VERSION ""

NS_ :

BS_:

BU_: VCM INVmc HVAC TCU OBCpd HVBAT

BO_ 3221225472 VECTOR__INDEPENDENT_SIG_MSG: 0 Vector__XXX
 SG_ Unknown_55B_5 m3 : 40|8@1+ (1,0) [0|0] "" Vector__XXX
 SG_ StopChargeMaybe : 52|4@1+ (1,0) [0|0] "" Vector__XXX
 SG_ Unknown_59E_3 : 32|8@1+ (1,0) [0|0] "" Vector__XXX
 SG_ Unknown_1D4_5 : 40|8@1+ (1,0) [0|0] "" Vector__XXX
 SG_ Unknown_1D4_6 : 48|8@1+ (1,0) [0|0] "" Vector__XXX
 SG_ HCM_WakeUpSleepCommand : 24|8@1+ (1,0) [0|0] "" Vector__XXX
 SG_ Unknown_50B_4 : 32|8@1+ (1,0) [0|0] "" Vector__XXX
 SG_ Unknown_50B_5 : 40|8@1+ (1,0) [0|0] "" Vector__XXX
 SG_ Unknown_50B_6 : 48|8@1+ (1,0) [0|0] "" Vector__XXX
 SG_ Unknown_50C_5_1 m1 : 40|8@1+ (1,0) [0|0] "" Vector__XXX
 SG_ Unknown_50C_5_0 m0 : 40|8@1+ (1,0) [0|0] "" Vector__XXX
 SG_ Unknown_50C_5_2 m2 : 40|8@1+ (1,0) [0|0] "" Vector__XXX
 SG_ Unknown_50C_5_3 m3 : 40|8@1+ (1,0) [0|0] "" Vector__XXX
 SG_ ALU_Question : 32|8@1+ (1,0) [0|0] "" Vector__XXX
 SG_ Mux_50C M : 24|1@1+ (1,0) [0|0] "" Vector__XXX
 SG_ TCSOC : 6|1@1+ (1,0) [0|0] "" Vector__XXX
 SG_ LB_HistData_HighLow_Voltage_Time : 0|4@1+ (1,0) [0|10] "times" Vector__XXX
 SG_ LB_HistData_Tempera_Wakeup_Phase : 9|7@1+ (1,-40) [-40|86] "degC" Vector__XXX
 SG_ LB_Historical_Data_Temperature : 17|7@1+ (1,-40) [-40|86] "degC" Vector__XXX
 SG_ LB_HistData_Integrated_Current : 24|8@1- (0.6,0) [-76.2|76.2] "Ah" Vector__XXX
 SG_ LB_HistData_Degrade_IntRes_Coeff : 33|7@1+ (1,0) [0|100] "%" Vector__XXX
 SG_ LB_Historical_Data_Cell_Voltage : 42|6@1+ (1,0) [0|4380] "mV" Vector__XXX
 SG_ DiagSomething2 : 16|8@1+ (1,0) [0|0] "" Vector__XXX
 SG_ OBC_NormalChargePortConnection : 43|2@0+ (1,0) [0|0] "" Vector__XXX
 SG_ Mux_5BC M : 32|4@1+ (1,0) [0|0] "" Vector__XXX
 SG_ ChargeBars m8 : 20|4@1+ (1,0) [0|15] "-" Vector__XXX
 SG_ CapacityBars m9 : 20|4@1+ (1,0) [0|15] "-" Vector__XXX

BO_ 1468 x5BC: 8 HVBAT
 SG_ LB_Remain_Capacity_GIDS : 7|10@0+ (1,0) [0|500] "gids" Vector__XXX
 SG_ LB_Remaining_Capacity_Segments_0 m0 : 16|8@1+ (1,0) [0|240] "" Vector__XXX
 SG_ LB_Temperature_Segment_For_Dash : 24|8@1+ (0.4166666,0) [0|100] "%" Vector__XXX
 SG_ LB_Capacity_Deterioration_Rate : 33|7@1+ (1,0) [0|100] "%" Vector__XXX
 SG_ LB_Remain_Cap_Segment_Swit_Flag M : 32|1@1+ (1,0) [0|1] "status" Vector__XXX
 SG_ LB_Output_Power_Limit_Reason : 45|3@1+ (1,0) [0|7] "modemask" Vector__XXX
 SG_ LB_Remain_Charge_Time_Condition : 41|5@0+ (1,0) [0|30] "modemask" Vector__XXX
 SG_ LB_Remain_Charge_Time : 52|13@0+ (1,0) [0|8190] "minutes" Vector__XXX
 SG_ LB_MaxGIDS : 44|1@1+ (1,0) [0|1] "" Vector__XXX
 SG_ LB_Remaining_Capacity_Segments_1 m1 : 16|8@1+ (1,0) [0|240] "" Vector__XXX

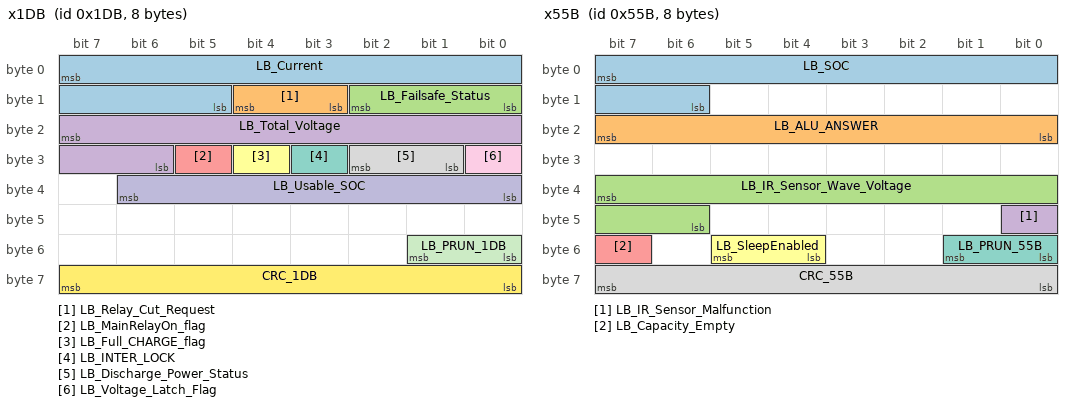
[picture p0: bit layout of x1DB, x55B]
BO_ 475 x1DB: 8 HVBAT
 SG_ LB_Current : 7|11@0- (0.5,0) [-400|200] "A" Vector__XXX
 SG_ LB_Relay_Cut_Request : 11|2@1+ (1,0) [0|0] "MODEMASK" Vector__XXX
 SG_ LB_Failsafe_Status : 8|3@1+ (1,0) [0|0] "MODEMASK" Vector__XXX
 SG_ LB_Total_Voltage : 23|10@0+ (0.5,0) [0|450] "V" Vector__XXX
 SG_ LB_MainRelayOn_flag : 29|1@1+ (1,0) [0|0] "MODEMASK" Vector__XXX
 SG_ LB_Full_CHARGE_flag : 28|1@1+ (1,0) [0|0] "" Vector__XXX
 SG_ LB_INTER_LOCK : 27|1@1+ (1,0) [0|0] "MODEMASK" Vector__XXX
 SG_ LB_Discharge_Power_Status : 25|2@1+ (1,0) [0|0] "MODEMASK" Vector__XXX
 SG_ LB_Voltage_Latch_Flag : 24|1@1+ (1,0) [0|0] "MODEMASK" Vector__XXX
 SG_ LB_Usable_SOC : 32|7@1+ (1,0) [0|0] "" Vector__XXX
 SG_ LB_PRUN_1DB : 48|2@1+ (1,0) [0|0] "" Vector__XXX
 SG_ CRC_1DB : 56|8@1+ (1,0) [0|0] "CRC" Vector__XXX

BO_ 1371 x55B: 8 HVBAT
 SG_ LB_SOC : 7|10@0+ (1,0) [0|1000] "%+1" Vector__XXX
 SG_ LB_ALU_ANSWER : 16|8@1+ (1,0) [85|170] "" Vector__XXX
 SG_ LB_IR_Sensor_Wave_Voltage : 39|10@0+ (1,0) [0|4990] "mV (5000/1024)" Vector__XXX
 SG_ LB_IR_Sensor_Malfunction : 40|1@1+ (1,0) [0|1] "modemask" Vector__XXX
 SG_ LB_Capacity_Empty : 55|1@1+ (1,0) [0|1] "modemask" Vector__XXX
 SG_ LB_SleepEnabled : 53|2@0+ (1,0) [0|3] "modemask" Vector__XXX
 SG_ LB_PRUN_55B : 48|2@1+ (1,0) [0|3] "" Vector__XXX
 SG_ CRC_55B : 56|8@1+ (1,0) [0|0] "CRC" Vector__XXX

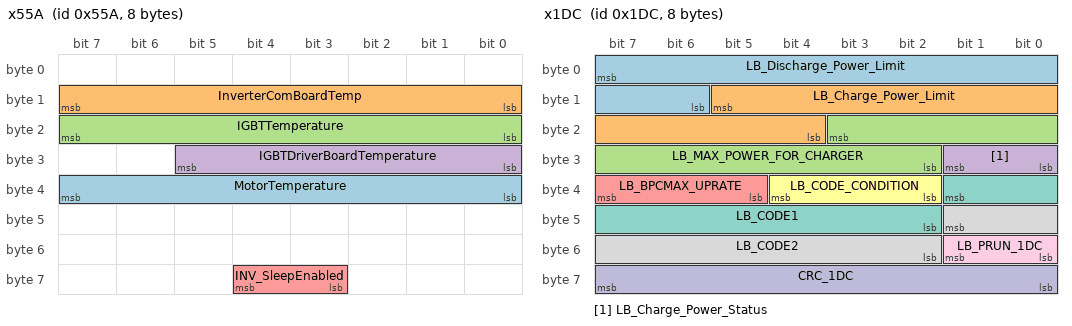
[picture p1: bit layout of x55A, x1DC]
BO_ 1370 x55A: 8 INVmc
 SG_ MotorTemperature : 32|8@1+ (1,0) [0|255] "dC*2" Vector__XXX
 SG_ InverterComBoardTemp : 8|8@1+ (1,0) [0|255] "dC*2" Vector__XXX
 SG_ IGBTTemperature : 16|8@1+ (1,0) [0|255] "dC*2" Vector__XXX
 SG_ IGBTDriverBoardTemperature : 29|6@0+ (1,0) [0|255] "dC*2" Vector__XXX
 SG_ INV_SleepEnabled : 60|2@0+ (1,0) [0|0] "" Vector__XXX

BO_ 476 x1DC: 8 HVBAT
 SG_ LB_Discharge_Power_Limit : 7|10@0+ (0.25,0) [0|254] "kW" Vector__XXX
 SG_ LB_Charge_Power_Limit : 13|10@0+ (0.25,0) [0|254] "kW" Vector__XXX
 SG_ LB_MAX_POWER_FOR_CHARGER : 19|10@0+ (0.1,-10) [-10|90] "kW" Vector__XXX
 SG_ LB_Charge_Power_Status : 24|2@1+ (1,0) [0|0] "MODEMASK" Vector__XXX
 SG_ LB_BPCMAX_UPRATE : 37|3@1+ (1,0) [0|0] "MODEMASK" Vector__XXX
 SG_ LB_CODE_CONDITION : 34|3@1+ (1,0) [0|0] "" Vector__XXX
 SG_ LB_CODE1 : 33|8@0+ (1,0) [0|0] "" Vector__XXX
 SG_ LB_CODE2 : 41|8@0+ (1,0) [0|0] "" Vector__XXX
 SG_ LB_PRUN_1DC : 48|2@1+ (1,0) [0|3] "" Vector__XXX
 SG_ CRC_1DC : 56|8@1+ (1,0) [0|0] "CRC" Vector__XXX

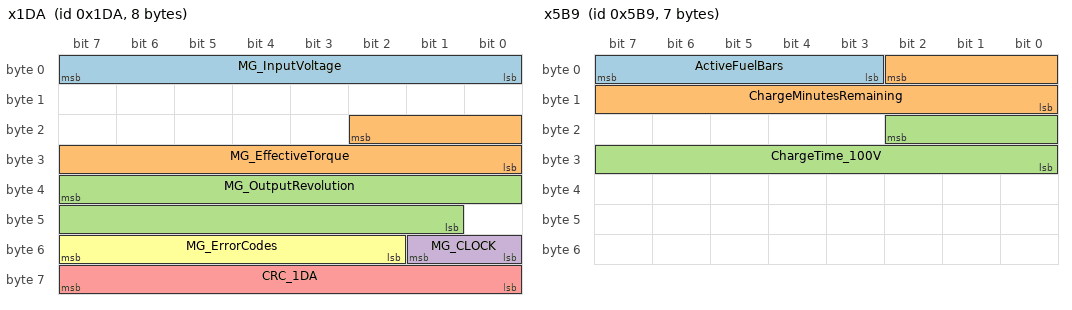
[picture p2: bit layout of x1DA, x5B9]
BO_ 474 x1DA: 8 INVmc
 SG_ MG_InputVoltage : 0|8@1+ (2,0) [0|508] "V" Vector__XXX
 SG_ MG_EffectiveTorque : 18|11@0- (0.5,0) [-274|274] "Nm" Vector__XXX
 SG_ MG_OutputRevolution : 39|15@0- (1,0) [-16382|16382] "rpm" Vector__XXX
 SG_ MG_CLOCK : 48|2@1+ (1,0) [0|3] "PRUN" Vector__XXX
 SG_ CRC_1DA : 56|8@1+ (1,0) [0|0] "CRC" Vector__XXX
 SG_ MG_ErrorCodes : 50|6@1+ (1,0) [0|0] "status" Vector__XXX

BO_ 1465 x5B9: 7 VCM
 SG_ ActiveFuelBars : 3|5@1+ (1,0) [0|12] "-" Vector__XXX
 SG_ ChargeMinutesRemaining : 2|11@0+ (1,0) [0|2047] "minutes" Vector__XXX
 SG_ ChargeTime_100V : 18|11@0+ (1,0) [0|0] "" Vector__XXX

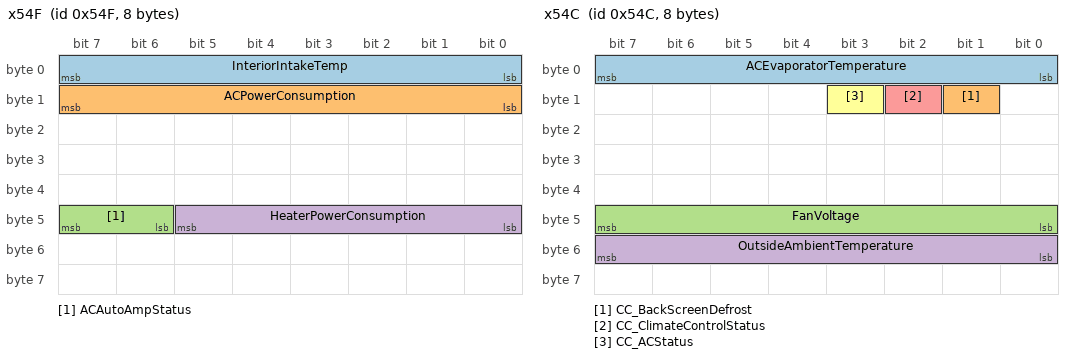
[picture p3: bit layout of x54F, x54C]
BO_ 1359 x54F: 8 HVAC
 SG_ InteriorIntakeTemp : 0|8@1+ (0.5,-14) [0|0] "degC" Vector__XXX
 SG_ ACPowerConsumption : 8|8@1+ (1,0) [0|0] "50W/bit?" Vector__XXX
 SG_ ACAutoAmpStatus : 46|2@1+ (1,0) [0|0] "-" Vector__XXX
 SG_ HeaterPowerConsumption : 40|6@1+ (1,0) [0|0] "300W/bit?" Vector__XXX

BO_ 1356 x54C: 8 HVAC
 SG_ ACEvaporatorTemperature : 0|8@1+ (1,0) [0|0] "0.25C/bit?" Vector__XXX
 SG_ CC_BackScreenDefrost : 9|1@1+ (1,0) [0|1] "-" Vector__XXX
 SG_ FanVoltage : 40|8@1+ (1,0) [0|0] "0.05 V/bit" Vector__XXX
 SG_ OutsideAmbientTemperature : 48|8@1+ (0.5,-40.5) [-40|60] "degC" Vector__XXX
 SG_ CC_ClimateControlStatus : 10|1@1+ (1,0) [0|1] "-" Vector__XXX
 SG_ CC_ACStatus : 11|1@1+ (1,0) [0|1] "-" Vector__XXX

BO_ 282 x11A: 8 VCM
 SG_ JoystickGearPosition : 4|4@1+ (1,0) [0|0] "-" Vector__XXX
 SG_ CarOnOffStatus : 15|2@0+ (1,0) [0|0] "-" Vector__XXX
 SG_ Mulitplexor M : 48|8@1+ (1,0) [0|0] "" Vector__XXX
 SG_ StartupDataUnknown0 m0 : 56|8@1+ (1,0) [0|0] "" Vector__XXX
 SG_ StartupDataUnknown1 m1 : 56|8@1+ (1,0) [0|0] "" Vector__XXX
 SG_ StartupDataUnknown2 m2 : 56|8@1+ (1,0) [0|0] "" Vector__XXX
 SG_ StartupDataUnknown3 m3 : 56|8@1+ (1,0) [0|0] "" Vector__XXX
 SG_ Unknown_11A_2_5 : 21|3@0+ (1,0) [0|0] "" Vector__XXX
 SG_ HeartbeatVCM : 24|8@1+ (1,0) [85|170] "" Vector__XXX
 SG_ Unknown_11A_4_0 m0 : 32|8@1+ (1,0) [0|0] "" Vector__XXX
 SG_ Unknown_11A_4_1 m1 : 32|8@1+ (1,0) [0|0] "" Vector__XXX
 SG_ Unknown_11A_4_2 m2 : 32|8@1+ (1,0) [0|0] "" Vector__XXX
 SG_ Unknown_11A_4_3 m3 : 32|8@1+ (1,0) [0|0] "" Vector__XXX
 SG_ ECOselected : 12|1@1+ (1,0) [0|0] "" Vector__XXX
 SG_ ELECTRIC_SHIFT_SYSTEM : 9|2@0+ (1,0) [0|0] "" Vector__XXX
 SG_ Unknown_11A_2_2 : 18|1@0+ (1,0) [0|0] "" Vector__XXX
 SG_ Unknown_11A_2_6 : 22|1@0+ (1,0) [0|0] "" Vector__XXX
 SG_ Unknown_11A_2_7 : 23|1@0+ (1,0) [0|0] "" Vector__XXX
 SG_ Unknown_11A_1_2 : 10|1@0+ (1,0) [0|0] "" Vector__XXX
 SG_ Unknown_11A_1_3 : 11|1@0+ (1,0) [0|0] "" Vector__XXX

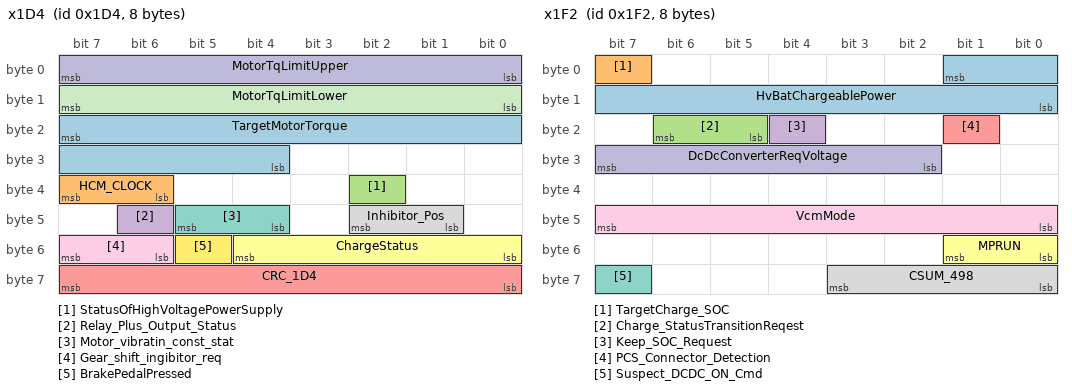
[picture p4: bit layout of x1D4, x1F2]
BO_ 468 x1D4: 8 VCM
 SG_ TargetMotorTorque : 23|12@0- (0.25,0) [0|1024] "Nm" Vector__XXX
 SG_ HCM_CLOCK : 38|2@1+ (1,0) [0|3] "-" Vector__XXX
 SG_ StatusOfHighVoltagePowerSupply : 34|1@1+ (1,0) [0|0] "-" Vector__XXX
 SG_ Relay_Plus_Output_Status : 46|1@1+ (1,0) [0|0] "-" Vector__XXX
 SG_ CRC_1D4 : 56|8@1+ (1,0) [0|255] "" Vector__XXX
 SG_ ChargeStatus : 52|5@0+ (1,0) [0|255] "MODEMASK" Vector__XXX
 SG_ Motor_vibratin_const_stat : 45|2@0+ (1,0) [0|0] "" Vector__XXX
 SG_ Inhibitor_Pos : 42|2@0+ (1,0) [0|0] "" Vector__XXX
 SG_ Gear_shift_ingibitor_req : 55|2@0+ (1,0) [0|0] "" Vector__XXX
 SG_ MotorTqLimitUpper : 7|8@0+ (2.5,0) [0|0] "Nm" Vector__XXX
 SG_ MotorTqLimitLower : 15|8@0+ (-2.5,0) [0|0] "Nm" Vector__XXX
 SG_ BrakePedalPressed : 53|1@0+ (1,0) [0|0] "" Vector__XXX

BO_ 498 x1F2: 8 VCM
 SG_ HvBatChargeablePower : 1|10@0+ (0.1,-10) [0|0] "" Vector__XXX
 SG_ TargetCharge_SOC : 7|1@1+ (1,0) [0|0] "modemask" Vector__XXX
 SG_ Charge_StatusTransitionReqest : 21|2@1+ (1,0) [0|3] "modemask" Vector__XXX
 SG_ Keep_SOC_Request : 20|1@1+ (1,0) [0|0] "modemask" Vector__XXX
 SG_ PCS_Connector_Detection : 17|1@1+ (1,0) [0|0] "modemask" Vector__XXX
 SG_ MPRUN : 48|2@1+ (1,0) [0|0] "" Vector__XXX
 SG_ Suspect_DCDC_ON_Cmd : 63|1@1+ (1,0) [0|0] "" Vector__XXX
 SG_ CSUM_498 : 56|4@1+ (1,0) [0|0] "" Vector__XXX
 SG_ VcmMode : 47|8@0+ (1,0) [0|0] "" Vector__XXX
 SG_ DcDcConverterReqVoltage : 31|6@0+ (0.1,-10) [0|0] "V" Vector__XXX

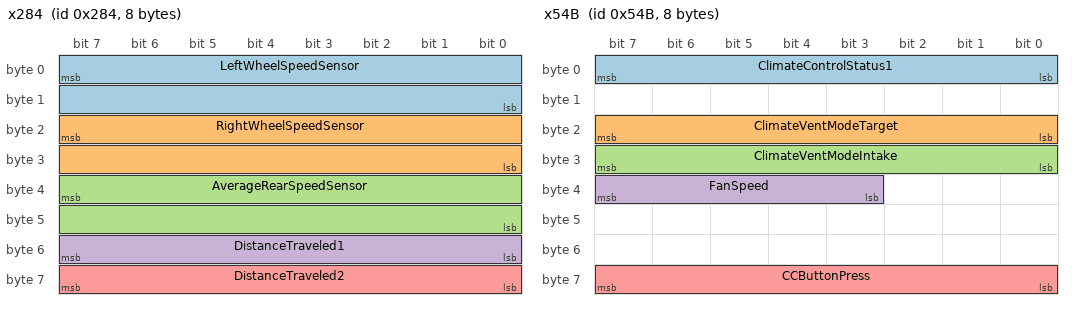
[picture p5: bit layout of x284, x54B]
BO_ 644 x284: 8 VCM
 SG_ LeftWheelSpeedSensor : 7|16@0+ (1,0) [0|65535] "pulses" Vector__XXX
 SG_ RightWheelSpeedSensor : 23|16@0+ (1,0) [0|65535] "pulses" Vector__XXX
 SG_ AverageRearSpeedSensor : 39|16@0+ (1,0) [0|65535] "pulses" Vector__XXX
 SG_ DistanceTraveled1 : 48|8@1+ (1,0) [0|255] "" Vector__XXX
 SG_ DistanceTraveled2 : 56|8@1+ (1,0) [0|255] "" Vector__XXX

BO_ 1355 x54B: 8 HVAC
 SG_ ClimateControlStatus1 : 0|8@1+ (1,0) [0|0] "status" Vector__XXX
 SG_ ClimateVentModeTarget : 16|8@1+ (1,0) [0|0] "status" Vector__XXX
 SG_ ClimateVentModeIntake : 24|8@1+ (1,0) [0|0] "status" Vector__XXX
 SG_ FanSpeed : 35|5@1+ (1,0) [1|7] "speed" Vector__XXX
 SG_ CCButtonPress : 56|8@1+ (1,0) [0|0] "0/1" Vector__XXX

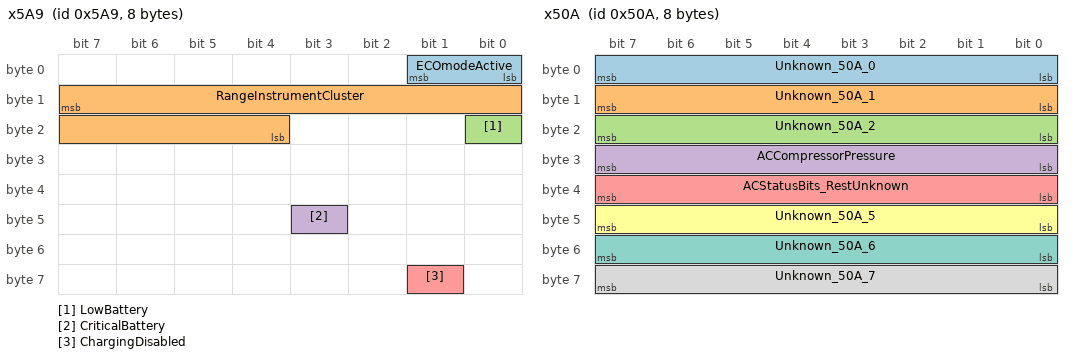
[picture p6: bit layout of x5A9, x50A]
BO_ 1449 x5A9: 8 VCM
 SG_ ECOmodeActive : 0|2@1+ (1,0) [0|0] "" Vector__XXX
 SG_ RangeInstrumentCluster : 15|12@0+ (0.2,0) [0|819] "km" Vector__XXX
 SG_ LowBattery : 16|1@1+ (1,0) [0|0] "" Vector__XXX
 SG_ CriticalBattery : 43|1@1+ (1,0) [0|0] "" Vector__XXX
 SG_ ChargingDisabled : 57|1@1+ (1,0) [0|0] "" Vector__XXX

BO_ 1472 x5C0: 8 HVBAT
 SG_ LB_Historical_Data_Swich_Flag M : 6|2@1+ (1,0) [0|3] "mux" Vector__XXX
 SG_ LB_Heating_Start_Send_Request : 5|1@1+ (1,0) [0|1] "status" Vector__XXX
 SG_ LB_Heating_Stop_Send_Request : 4|1@1+ (1,0) [0|1] "status" Vector__XXX
 SG_ Batt_Heater_Mail_Send_Request : 8|1@1+ (1,0) [0|1] "status" Vector__XXX
 SG_ LB_HEATEXIST : 32|1@1+ (1,0) [0|1] "status" Vector__XXX
 SG_ LB_NextWakeupTimeForBatterHeater : 48|5@1+ (1,0) [0|1800] "minutes" Vector__XXX
 SG_ LB_Diagnosis_Trouble_Code : 56|8@1+ (1,0) [0|255] "DTC" Vector__XXX
 SG_ LB_HistData_HighLow_Volt_Tim_MIN m3 : 0|4@1+ (1,0) [0|10] "times" Vector__XXX
 SG_ LB_HistData_HighLow_Volt_Tim_MAX m1 : 0|4@1+ (1,0) [0|10] "times" Vector__XXX
 SG_ LB_HistData_HighLow_Volt_Tim_AVG m2 : 0|4@1+ (1,0) [0|10] "times" Vector__XXX
 SG_ LB_HistData_Temp_WakeupPhase_MIN m3 : 9|7@1+ (0.5,-40) [-40|86] "degC" Vector__XXX
 SG_ LB_HistData_Temp_WakeupPhase_MAX m1 : 9|7@1+ (0.5,-40) [-40|86] "degC" Vector__XXX
 SG_ LB_HistData_Temp_WakeupPhase_AVG m2 : 9|7@1+ (0.5,-40) [-40|86] "degC" Vector__XXX
 SG_ LB_HistData_Temperature_MIN m3 : 17|7@1+ (0.5,-40) [-40|86] "degC" Vector__XXX
 SG_ LB_HistData_Temperature_MAX m1 : 17|7@1+ (0.5,-40) [-40|86] "degC" Vector__XXX
 SG_ LB_HistData_Temperature_AVG m2 : 17|7@1+ (0.5,-40) [-40|86] "degC" Vector__XXX
 SG_ LB_HistData_IntegratedCurrentMIN m3 : 24|8@1+ (0.6,0) [-76.2|76.2] "Ah" Vector__XXX
 SG_ LB_HistData_IntegratedCurrentMAX m1 : 24|8@1+ (0.6,0) [-76.2|76.2] "Ah" Vector__XXX
 SG_ LB_HistData_IntegratedCurrentAVG m2 : 24|8@1+ (0.6,0) [-76.2|76.2] "Ah" Vector__XXX
 SG_ LB_HistData_Degr_IntRes_CoeffMIN m3 : 33|7@1+ (1,0) [0|100] "%" Vector__XXX
 SG_ LB_HistData_Degr_IntRes_CoeffMAX m1 : 33|7@1+ (1,0) [0|100] "%" Vector__XXX
 SG_ LB_HistData_Degr_IntRes_CoeffAVG m2 : 33|7@1+ (1,0) [0|100] "%" Vector__XXX
 SG_ LB_HistData_Cell_Voltage_MIN m3 : 42|6@1+ (40,1900) [0|4380] "mV" Vector__XXX
 SG_ LB_HistData_Cell_Voltage_MAX m1 : 42|6@1+ (40,1900) [0|4380] "mV" Vector__XXX
 SG_ LB_HistData_Cell_Voltage_AVG m2 : 42|6@1+ (40,1900) [0|4380] "mV" Vector__XXX

BO_ 1290 x50A: 8 VCM
 SG_ Unknown_50A_0 : 0|8@1+ (1,0) [0|0] "" Vector__XXX
 SG_ Unknown_50A_1 : 8|8@1+ (1,0) [0|0] "" Vector__XXX
 SG_ Unknown_50A_2 : 16|8@1+ (1,0) [0|0] "" Vector__XXX
 SG_ ACCompressorPressure : 24|8@1+ (1,0) [0|0] "" Vector__XXX
 SG_ ACStatusBits_RestUnknown : 32|8@1+ (1,0) [0|0] "" Vector__XXX
 SG_ Unknown_50A_5 : 40|8@1+ (1,0) [0|0] "" Vector__XXX
 SG_ Unknown_50A_6 : 48|8@1+ (1,0) [0|0] "" Vector__XXX
 SG_ Unknown_50A_7 : 56|8@1+ (1,0) [0|0] "" Vector__XXX

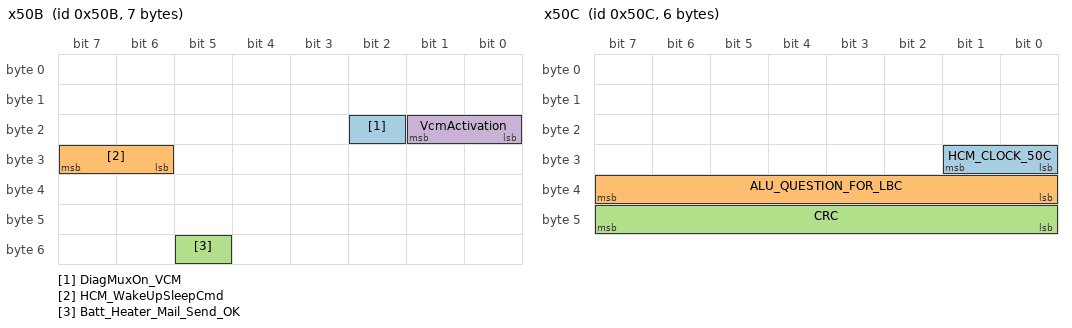
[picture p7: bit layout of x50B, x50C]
BO_ 1291 x50B: 7 VCM
 SG_ DiagMuxOn_VCM : 18|1@1+ (1,0) [0|0] "" Vector__XXX
 SG_ HCM_WakeUpSleepCmd : 30|2@1+ (1,0) [0|0] "" Vector__XXX
 SG_ Batt_Heater_Mail_Send_OK : 53|1@1+ (1,0) [0|0] "" Vector__XXX
 SG_ VcmActivation : 17|2@0+ (1,0) [0|0] "" Vector__XXX

BO_ 1292 x50C: 6 VCM
 SG_ HCM_CLOCK_50C : 24|2@1+ (1,0) [0|0] "" Vector__XXX
 SG_ ALU_QUESTION_FOR_LBC : 32|8@1+ (1,0) [0|0] "" Vector__XXX
 SG_ CRC : 40|8@1+ (1,0) [0|0] "CRC" Vector__XXX

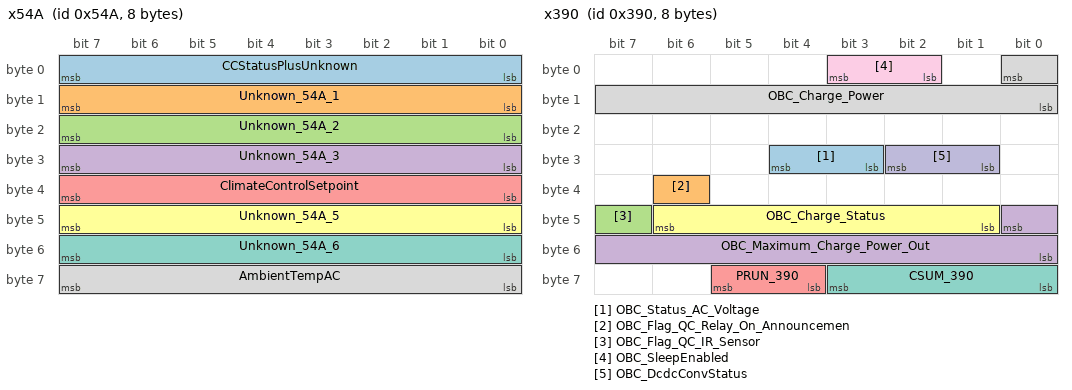
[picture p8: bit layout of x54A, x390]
BO_ 1354 x54A: 8 HVAC
 SG_ CCStatusPlusUnknown : 0|8@1+ (1,0) [0|0] "" Vector__XXX
 SG_ Unknown_54A_1 : 8|8@1+ (1,0) [0|0] "" Vector__XXX
 SG_ Unknown_54A_2 : 16|8@1+ (1,0) [0|0] "" Vector__XXX
 SG_ Unknown_54A_3 : 24|8@1+ (1,0) [0|0] "" Vector__XXX
 SG_ ClimateControlSetpoint : 32|8@1+ (1,0) [0|0] "" Vector__XXX
 SG_ Unknown_54A_5 : 40|8@1+ (1,0) [0|0] "" Vector__XXX
 SG_ Unknown_54A_6 : 48|8@1+ (1,0) [0|0] "" Vector__XXX
 SG_ AmbientTempAC : 56|8@1+ (1,0) [0|0] "" Vector__XXX

BO_ 1118 x45E: 1 Vector__XXX

BO_ 1438 x59E: 8 HVBAT
 SG_ LB_Full_Capacity_for_QC : 20|9@0+ (100,0) [0|50000] "Wh" Vector__XXX
 SG_ LB_Remain_Capacity_for_QC : 27|9@0+ (100,0) [0|50000] "Wh" Vector__XXX

BO_ 1153 x481: 2 Vector__XXX
 SG_ Unknown_481_1 : 0|8@1+ (1,0) [0|0] "" Vector__XXX
 SG_ Unknown_481_2 : 8|8@1+ (1,0) [0|0] "" Vector__XXX

BO_ 912 x390: 8 OBCpd
 SG_ OBC_Status_AC_Voltage : 27|2@1+ (1,0) [0|3] "status" Vector__XXX
 SG_ OBC_Flag_QC_Relay_On_Announcemen : 38|1@1+ (1,0) [0|1] "status" Vector__XXX
 SG_ OBC_Flag_QC_IR_Sensor : 47|1@1+ (1,0) [0|1] "status" Vector__XXX
 SG_ OBC_Maximum_Charge_Power_Out : 40|9@0+ (0.1,0) [0|50] "kW" Vector__XXX
 SG_ PRUN_390 : 60|2@1+ (1,0) [0|3] "PRUN" Vector__XXX
 SG_ OBC_Charge_Status : 46|6@0+ (1,0) [0|0] "status" Vector__XXX
 SG_ CSUM_390 : 56|4@1+ (1,0) [0|16] "CSUM" Vector__XXX
 SG_ OBC_Charge_Power : 0|9@0+ (0.1,0) [0|50] "kW" Vector__XXX
 SG_ OBC_SleepEnabled : 3|2@0+ (1,0) [0|0] "" Vector__XXX
 SG_ OBC_DcdcConvStatus : 26|2@0+ (1,0) [0|0] "" Vector__XXX

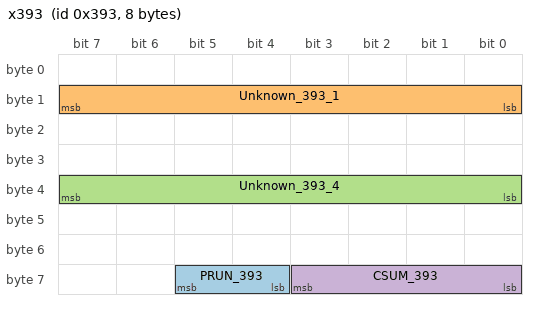
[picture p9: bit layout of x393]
BO_ 915 x393: 8 OBCpd
 SG_ PRUN_393 : 60|2@1+ (1,0) [0|3] "PRUN" Vector__XXX
 SG_ Unknown_393_1 : 8|8@1+ (1,0) [0|0] "" Vector__XXX
 SG_ Unknown_393_4 : 32|8@1+ (1,0) [0|0] "" Vector__XXX
 SG_ CSUM_393 : 56|4@1+ (1,0) [0|0] "CSUM" Vector__XXX

BO_ 1539 x603: 8 VCM

BO_ 1657 x679: 1 OBCpd

BO_ 1390 x56E: 1 TCU
 SG_ Unknown_56E_0 : 0|8@1+ (1,0) [0|0] "" Vector__XXX

BO_ 1549 x60D: 8 Vector__XXX
 SG_ Unknown_60D_0 : 0|8@1+ (1,0) [0|0] "" Vector__XXX
 SG_ Unknown_60D_1 : 8|8@1+ (1,0) [0|0] "" Vector__XXX

CM_ BU_ VCM "Vehicle Control Module";
CM_ BU_ INVmc "Inverter Motor Controller";
CM_ BU_ HVAC "Heating Ventilation and Air Conditioning";
CM_ BU_ TCU "Telematics Control Unit";
CM_ BU_ OBCpd "On Board Charger power distribution";
CM_ BU_ HVBAT "High Voltage Battery (Lithium Battery Controller)";
CM_ SG_ 3221225472 Unknown_59E_3 "Dala: DEC 152, 144, 136 seen here in short log";
CM_ SG_ 3221225472 Unknown_50B_4 "00";
CM_ SG_ 3221225472 Unknown_50C_5_1 "Dala, def muxed";
CM_ SG_ 3221225472 Unknown_50C_5_0 "Dala, def muxed

Mux 1 and 2 look like the inverse of 0 and 3";
CM_ SG_ 3221225472 Unknown_50C_5_2 "Dala, def muxed";
CM_ SG_ 3221225472 Unknown_50C_5_3 "Dala, def muxed";
CM_ SG_ 3221225472 ALU_Question "5d,b2 Dala: Used for backwardscompability?";
CM_ SG_ 3221225472 Mux_50C "0,1,2,3";
CM_ SG_ 3221225472 TCSOC "Position in frame?";
CM_ SG_ 3221225472 LB_HistData_Integrated_Current "2S";
CM_ SG_ 3221225472 Mux_5BC "Multiplexor";
CM_ SG_ 3221225472 ChargeBars "Range 0-15 (Below data from test at 0%SOC, writing values to bus)
15 = 12 chargebars
14 = 12 chargebars
13 = 11 chargebars
12 = 10 chargebars
11 = 9 chargebars
10 = 8 chargebars !
9 = 8 chargebars !
8 = 7 chargebars
7 = 6 chargebars
6 = 5 chargebars
5 = 4 chargebars !
4 = 4 chargebars !
3 = 3 chargebars
2 = 2 chargebars
1 = 1 chargebars
0 = 0 chargebars";
CM_ SG_ 3221225472 CapacityBars "Range 0-15 Below test data by writing to bus and seeing what happens
15 = 12 capacitybars
14 = 12 capacitybars
13 = 11 capacitybars
12 = 10 capacitybars
11 = 9 capacitybars
10 = 8 capacitybars !
9 = 8 capacitybars !
8 = 7 capacitybars
7 = 6 capacitybars
6 = 5 capacitybars
5 = 4 capacitybars !
4 = 4 capacitybars !
3 = 3 capacitybars
2 = 2 capacitybars
1 = 1 capacitybars
0 = 0 capacitybars,";
CM_ BO_ 1468 "Lithium Battery Controller (100ms)";
CM_ SG_ 1468 LB_Remain_Capacity_GIDS "0-281 for 24kWh, 0-363 for 30kWh, 0-498 for 40kWh, 0-775 for 62kWh
1 LSB = 80WH

LB_CAPR (aka 'gids') is an 80Wh resolution capacity indication used by the GOM and combined with LB_FULLCAP on gen1 Leafs to generate the capacity dashes behind the GOM.";
CM_ SG_ 1468 LB_Remaining_Capacity_Segments_0 "Remaining capacity segments (Follows LB_CAPSW)";
CM_ SG_ 1468 LB_Temperature_Segment_For_Dash "For instrumentation cluster. Unit is %, times 5/12 according to documentation, kinda strange .Should be average of the 3 sensors inside the battery pack.";
CM_ SG_ 1468 LB_Capacity_Deterioration_Rate "SOH (State-of-Health) Effects the charge gauge, lower numbers mean more chargebars";
CM_ SG_ 1468 LB_Output_Power_Limit_Reason "Indicates why power is limited";
CM_ SG_ 1468 LB_Remain_Charge_Time_Condition "Mux for LB_Remain_charge_time

00000b = Quick charge 01001b = Normal Charge 200V SOC100% 01010b = Normal Charge 200V SOC80% 10001b = Normal Charge 100V SOC100% 10010b = Normal Charge 100V SOC80% 11111b = Invalid value";
CM_ SG_ 1468 LB_Remain_Charge_Time "1FFFh is used as \"Unavailable value\"";
CM_ SG_ 1468 LB_MaxGIDS "Only 30kWh AZE0 has this. When this value is 1, the GIDS number is at its maximum.(LB_Remain_Capacity_GIDS)";
CM_ SG_ 1468 LB_Remaining_Capacity_Segments_1 "Full capacity segments (Follows LB_CAPSW)";
CM_ BO_ 475 "Lithium Battery Controller (10ms)";
CM_ SG_ 475 LB_Current "BatteryCurrentSignal , 2s comp, 1lSB = 0.5A";
CM_ SG_ 475 LB_Relay_Cut_Request "00 = No-Request 01 = Main Relay OFF Request 10 = Main Relay OFF Request 11 = Main Relay OFF Request";
CM_ SG_ 475 LB_Failsafe_Status "Request Stop charging. This is the command to request stop charging
frame.data[1] = (frame.data[1] & 0xE0) | 2;

Bit 0 indicates an EV system error (just the EV system warning light on the dash), bit 1 stops the car from charging and bit 2 is the turtle light and immobilizes the car.

000b = normal start Request 001b = Normal Stop Request 010b = Charging Mode Stop Request 011b = Charging Mode Stop Request & Normal Stop Request 100b = Caution Lamp Request 101b = Caution Lamp Request & Normal Stop Request 110b = Caution Lamp Request & Charging Mode Stop Request 111b = Caution Lamp Request & Charging Mode Stop Request & Normal Stop Request";
CM_ SG_ 475 LB_Total_Voltage "0.5V/bit
";
CM_ SG_ 475 LB_MainRelayOn_flag "0h = No-Permission 1h = Main Relay On Permission";
CM_ SG_ 475 LB_INTER_LOCK "0h = Not Inter Lock connected 1h = Inter Lock connected";
CM_ SG_ 475 LB_Discharge_Power_Status "00b = Reserved 01b = Normal limit POUT 10b = High rate limit POUT 11b = Immediate limit POUT";
CM_ SG_ 475 LB_Voltage_Latch_Flag "0->1:Cell Voltage Latch
1->0:Cell Voltage Latch";
CM_ SG_ 475 LB_Usable_SOC "Contains SOC for dash. LB_USABLE_SOC is a 1% resolution 'proper' SOC calculated by the LBC and used by ABB chargers and the SOC display in the dash menu as well as the 3-light charging indicator on top of the dash [Needs to be copied to this location when doing 40/62kWh swaps into AZE0]";
CM_ SG_ 475 LB_PRUN_1DB "MPR1DB Detection of frozen data. Message-PRUN-Diag. The transmitting node adds a message counter of 2bits or more to the end of the last data area (or just before the checksum). The value of the counter, which is initially 0, increments by one everytime new data is transmitted, and returned to zero when reaching the max value. The receiving node lets the first message pass without check, but for second next message and following, it check whether the counter number is different from the previous message.";
CM_ SG_ 475 CRC_1DB "CRC";
CM_ BO_ 1371 "Lithium Battery Controller (100ms)";
CM_ SG_ 1371 LB_SOC "State of charge. LB_SOC is a 0.1% resolution SOC that is used on startup by Leaf Spy Pro and then ignored in favor of 0x7BB groups, and seemingly used nowhere in the car";
CM_ SG_ 1371 LB_ALU_ANSWER "HCM:B2h LBC:AAh HCM:5Dh LBC:55h

This message is repeated 5x, to offer backwardscompability to 2011/2013 models? The message on these cars are run at 500ms.";
CM_ SG_ 1371 LB_IR_Sensor_Wave_Voltage "Internal resistance wave voltage";
CM_ SG_ 1371 LB_IR_Sensor_Malfunction "Note! LB_IRSEN is the IR sensor fault flag - This flag can be set in salvage packs because the car itself has had an isolation fault, due to impact damage, and LB_IRSEN doesn't clear for a good long time after it's been set. Not possible to clear with Leafspy!

If you encounter this error, drop the battery pack and open it up. Inspect for water intrusion.";
CM_ SG_ 1371 LB_PRUN_55B "Detection of frozen data. Message-PRUN-Diag. The transmitting node adds a message counter of 2bits or more to the end of the last data area (or just before the checksum). The value of the counter, which is initially 0, increments by one everytime new data is transmitted, and returned to zero when reaching the max value. The receiving node lets the first message pass without check, but for second next message and following, it check whether the counter number is different from the previous message.";
CM_ SG_ 1371 CRC_55B "CRC";
CM_ BO_ 1370 "Inverter (100ms)";
CM_ SG_ 1370 InverterComBoardTemp "Inverter communications board temp";
CM_ SG_ 1370 IGBTDriverBoardTemperature "Temperature only active during drive (IGBT driver board?)";
CM_ BO_ 476 "Lithium Battery Controller (10ms)";
CM_ SG_ 476 LB_Discharge_Power_Limit "Max available power that can be pulled from battery";
CM_ SG_ 476 LB_Charge_Power_Limit "Max power that battery can be charged with";
CM_ SG_ 476 LB_MAX_POWER_FOR_CHARGER "LB_BPCMAX";
CM_ SG_ 476 LB_Charge_Power_Status "00b = Reserved 01b = Normal limit PIN 10b = High rate limit PIN 11b = Immediate limit PIN";
CM_ SG_ 476 LB_BPCMAX_UPRATE "BPC MAX Uprate Level 1-8. Dala: (CAN-bridge testing) This value specifies how quickly the VCM follows the requested power in \"LB_MAX_POWER_FOR_CHARGER\".ZE0 Example, if Level 1 is selected and battery requests 45kW of quickcharging power, it will take 8minutes for power to ramp up from 0kW->45kW. If Level 8 is selected, it will take not ramp at all, and just intantaneously follow the requested power. If low level is forced, some quickcharging stations will fail to charge the vehicle, with an error message stating that too low current was demanded. Special notes for AZE0, the newer AZE0 VCM will ramp more aggressively at level 1 compared to ZE0, and no issues with fastcharging even though slow ramp rate is selected.";
CM_ SG_ 476 LB_PRUN_1DC "Detection of frozen data. Message-PRUN-Diag. The transmitting node adds a message counter of 2bits or more to the end of the last data area (or just before the checksum). The value of the counter, which is initially 0, increments by one everytime new data is transmitted, and returned to zero when reaching the max value. The receiving node lets the first message pass without check, but for second next message and following, it check whether the counter number is different from the previous message.";
CM_ SG_ 476 CRC_1DC "CRC";
CM_ BO_ 474 "Inverter (10ms)";
CM_ SG_ 474 MG_InputVoltage "VHMG - Inverter output voltage?

01..b9 Follows BVS(BatteryVoltageSignal) until near end of drive (turtle?) or end of charging ";
CM_ SG_ 474 MG_EffectiveTorque "STMG -  Response from Inverter how much torque was applied (Demand is in 0x1D4) Note that value is 2S!";
CM_ SG_ 474 MG_OutputRevolution "RNMG - Signed value, negative for reverse.

Values 0x7fff and 0x7ffe are seen during turning on of car";
CM_ SG_ 474 MG_CLOCK "Detection of frozen data. Message-PRUN-Diag. The transmitting node adds a message counter of 2bits or more to the end of the last data area (or just before the checksum). The value of the counter, which is initially 0, increments by one everytime new data is transmitted, and returned to zero when reaching the max value. The receiving node lets the first message pass without check, but for second next message and following, it check whether the counter number is different from the previous message.";
CM_ SG_ 474 CRC_1DA "CRC";
CM_ SG_ 474 MG_ErrorCodes "Contains info about error codes blocking inverter operation.
Possible causes not identified yet, but good starting point:
- HV missing (180V within 10s)
- too high temperature
- CAN messages not detected within 2s after poweron";
CM_ BO_ 1465 "Vehicle Control Module (500ms) (Only env200 and USDM LEAF?)";
CM_ SG_ 1465 ActiveFuelBars "From VCM->Cluster";
CM_ SG_ 1465 ChargeMinutesRemaining "Minutes from 3kW charging estimate on dash.

Example:
0x09 FE
0000 1001 1111 1110
001 1111 1110 = 510min";
CM_ BO_ 1359 "AC Auto Amp (100ms)";
CM_ SG_ 1359 InteriorIntakeTemp "Climate control's measurement of temperature inside the car. Subtracting 14 is a bit of a guess worked out by observing how auto climate control reacts when this reaches the target setting.";
CM_ SG_ 1359 ACPowerConsumption "Rises to a steady value with ac on.  Off immediately with ac off.  No change with heater on";
CM_ SG_ 1359 ACAutoAmpStatus "location?";
CM_ SG_ 1359 HeaterPowerConsumption "Goes up slowly with heater on; no change with ac on";
CM_ BO_ 1356 "AC Auto Amp (100ms)";
CM_ SG_ 1356 ACEvaporatorTemperature "drops with ac on (after short lag).  No change with heater on";
CM_ SG_ 1356 CC_BackScreenDefrost "Data only changes if climate control is activated or deactivated";
CM_ SG_ 1356 FanVoltage "Commanded fan speed is proportional to Voltage";
CM_ SG_ 1356 OutsideAmbientTemperature "Ambient temperature. This one has half-degree C resolution and seems to stay within a degree or two of the \"eyebrow\" temp display.";
CM_ SG_ 1356 CC_ClimateControlStatus "Data only changes if climate control is activated or deactivated";
CM_ SG_ 1356 CC_ACStatus "Data only changes if climate control is activated or deactivated";
CM_ BO_ 282 "Vehicle Control Module (10ms)

Shift controller module for 2011-2012 ZE0";
CM_ SG_ 282 JoystickGearPosition "(MSBits selected gear: 4 for D/B, 3 for N, 2 for R,0 for Parked)";
CM_ SG_ 282 Mulitplexor "0, 1, 2, 3";
CM_ SG_ 282 StartupDataUnknown0 "Activity only during startup, then holds a constant value for each channel";
CM_ SG_ 282 StartupDataUnknown1 "Activity only during startup, then holds a constant value for each channel";
CM_ SG_ 282 StartupDataUnknown2 "Activity only during startup, then holds a constant value for each channel";
CM_ SG_ 282 StartupDataUnknown3 "Activity only during startup, then holds a constant value for each channel";
CM_ SG_ 282 Unknown_11A_2_5 "00,04,80 observed here";
CM_ SG_ 282 HeartbeatVCM "55,AA (alternating between these two values, heartbeat?)
01010101
10101010";
CM_ SG_ 282 ECOselected "If set, ECO mode is active and regen is increased";
CM_ BO_ 468 "Vehicle Control Module (10ms)";
CM_ SG_ 468 TargetMotorTorque "Requested Torque sent to inverter";
CM_ SG_ 468 HCM_CLOCK "PRUN Detection of frozen data. Message-PRUN-Diag. The transmitting node adds a message counter of 2bits or more to the end of the last data area (or just before the checksum). The value of the counter, which is initially 0, increments by one everytime new data is transmitted, and returned to zero when reaching the max value. The receiving node lets the first message pass without check, but for second next message and following, it check whether the counter number is different from the previous message.";
CM_ SG_ 468 StatusOfHighVoltagePowerSupply "BTONFN";
CM_ SG_ 468 Relay_Plus_Output_Status "RLYP";
CM_ SG_ 468 ChargeStatus "During charging, the first 3 MSBs are high, and if user aborts charge, the highest MSB will go low. Useful for detecting that charge was interrupted by user unplugging the charge cable.";
CM_ BO_ 498 "Vehicle Control Module (10ms)";
CM_ SG_ 498 TargetCharge_SOC "TCSOC";
CM_ SG_ 498 Charge_StatusTransitionReqest "CHG_STA_RQ";
CM_ SG_ 498 Keep_SOC_Request "KEEP_SOC_REQ When the temperature in the battery pack is low outside the timer charge set time, VCM transmists a keep SOC request signal to LBC via CAN. In this case, the battery is not charged, and only battery heater is activated.";
CM_ SG_ 498 PCS_Connector_Detection "PSCONDET";
CM_ SG_ 498 MPRUN "Detection of frozen data. Message-PRUN-Diag. The transmitting node adds a message counter of 2bits or more to the end of the last data area (or just before the checksum). The value of the counter, which is initially 0, increments by one everytime new data is transmitted, and returned to zero when reaching the max value. The receiving node lets the first message pass without check, but for second next message and following, it check whether the counter number is different from the previous message.";
CM_ SG_ 498 Suspect_DCDC_ON_Cmd "Suspect - may indicate DCDC ON/OFF command";
CM_ SG_ 498 CSUM_498 "Checksum. All message nibbles summed together, plus 2. End result in hex is anded with 0xF.";
CM_ SG_ 498 VcmMode "Unknown values. Consult provides raw data 0-255";
CM_ BO_ 644 "ABS module relayed via VCM to EV-CAN (20ms)";
CM_ SG_ 644 LeftWheelSpeedSensor "2's comp";
CM_ SG_ 644 RightWheelSpeedSensor "2's comp";
CM_ SG_ 644 AverageRearSpeedSensor "??? speed sensor.  Maybe average of both rear? Or VehicleSpeedFromABS?";
CM_ SG_ 644 DistanceTraveled1 "00..ff (wraps ~360 times in a 25 mile drive)";
CM_ SG_ 644 DistanceTraveled2 "00..ff (wraps ~360 times in a 25 mile drive)";
CM_ BO_ 1355 "AC Auto Amp (100ms)";
CM_ SG_ 1355 ClimateControlStatus1 "00 CC on, 01 CC off (2013: 0x10 or 0x11)";
CM_ SG_ 1355 ClimateVentModeTarget "(face/feet/defrost)";
CM_ SG_ 1355 ClimateVentModeIntake "(recirculating/fresh air/defrost)";
CM_ SG_ 1355 FanSpeed "1<->7 ";
CM_ SG_ 1355 CCButtonPress "Alternates after every CC button press, probably to alert A/V to display CC info";
CM_ BO_ 1449 "Vehicle Control Module (100ms)

This message appeared after recall/update in March 2012. Probably VCM to TCU for carwings (engineering data)";
CM_ SG_ 1449 ECOmodeActive "Active during drive, FF charge";
CM_ SG_ 1449 RangeInstrumentCluster "Taken from OVMS code. 0xFFF when charging";
CM_ SG_ 1449 LowBattery "Low Battery (Message and tell-tale)";
CM_ SG_ 1449 CriticalBattery "GOM Flash (critical battery)";
CM_ SG_ 1449 ChargingDisabled "Charging Disabled, Battery Lease Contract";
CM_ BO_ 1472 "Lithium Battery Controller (500ms)";
CM_ SG_ 1472 LB_Historical_Data_Swich_Flag "Mux for historical data signals";
CM_ SG_ 1472 LB_Heating_Start_Send_Request "0->1 Heat start Mail send request";
CM_ SG_ 1472 LB_Heating_Stop_Send_Request "0->1 Heat stop Mail send request";
CM_ SG_ 1472 LB_HEATEXIST "Specifies if battery pack is equipped with heating elements";
CM_ SG_ 1472 LB_Diagnosis_Trouble_Code "Up to 2 error codes are indicated concurrently. If concurrent indication, they are sent alternately on each 500ms update cycle.

Start-up restriction by LB_DTC:
Wait on error stop mode and not to start-up when LB_DTC=153~200 is received during system start-up or operation.";
CM_ SG_ 1472 LB_HistData_HighLow_Volt_Tim_MIN "LB_Historical_Data_High_or_Low_Voltage_Times";
CM_ SG_ 1472 LB_HistData_HighLow_Volt_Tim_MAX "LB_Historical_Data_High_or_Low_Voltage_Times";
CM_ SG_ 1472 LB_HistData_HighLow_Volt_Tim_AVG "LB_Historical_Data_High_or_Low_Voltage_Times";
CM_ SG_ 1472 LB_HistData_Temp_WakeupPhase_MIN "LB_Historical_Data_Temperature_Wakeup_Phase";
CM_ SG_ 1472 LB_HistData_Temp_WakeupPhase_MAX "LB_Historical_Data_Temperature_Wakeup_Phase";
CM_ SG_ 1472 LB_HistData_Temp_WakeupPhase_AVG "LB_Historical_Data_Temperature_Wakeup_Phase";
CM_ SG_ 1472 LB_HistData_IntegratedCurrentMIN "2S

LB_Historical_Data_Integrated_Current";
CM_ SG_ 1472 LB_HistData_IntegratedCurrentMAX "2S

LB_Historical_Data_Integrated_Current";
CM_ SG_ 1472 LB_HistData_IntegratedCurrentAVG "2S

LB_Historical_Data_Integrated_Current";
CM_ SG_ 1472 LB_HistData_Degr_IntRes_CoeffMIN "LB_Historical_Data_Degradation_Internal_Resistance_Coefficient Dala: Trending MIN/MAX/AVG is strange. MAX/MIN sits at 100, AVG sits at 99";
CM_ SG_ 1472 LB_HistData_Degr_IntRes_CoeffMAX "LB_Historical_Data_Degradation_Internal_Resistance_Coefficient";
CM_ SG_ 1472 LB_HistData_Degr_IntRes_CoeffAVG "LB_Historical_Data_Degradation_Internal_Resistance_Coefficient";
CM_ SG_ 1472 LB_HistData_Cell_Voltage_MIN "Dala: Trending MIN/MAX/AVG is strange. AVG/MIN sits round 3700mV, MAX sits at 2100mV";
CM_ BO_ 1290 "SEE CAR CAN FILE



VCM relay from A/C Auto Amp and AC Pressor Sensor (which is measured directly from VCM) (100ms)

Message is identical on EV CAN and CAR CAN";
CM_ SG_ 1290 Unknown_50A_0 "04,84,85";
CM_ SG_ 1290 Unknown_50A_1 "02,13,33,40,42,53,72,73";
CM_ SG_ 1290 Unknown_50A_2 "00,a0";
CM_ SG_ 1290 ACCompressorPressure "Some sort of pressure/temperature?? 2c-44;

rises with AC on; slow decay when off";
CM_ SG_ 1290 ACStatusBits_RestUnknown "00,80  BIT1 = Rear defrost on/off";
CM_ SG_ 1290 Unknown_50A_5 "a0";
CM_ SG_ 1290 Unknown_50A_6 "04 , Only present in 2013+ (otherwise frame stops at 6bytes)";
CM_ SG_ 1290 Unknown_50A_7 "00 , Only present in 2013+ (otherwise frame stops at 6bytes)";
CM_ BO_ 1291 "Vehicle Control Module (100ms)";
CM_ SG_ 1291 DiagMuxOn_VCM "CANMASK";
CM_ SG_ 1291 HCM_WakeUpSleepCmd "FirstFrameValueIfAlgorithmNotReady = 3";
CM_ BO_ 1292 "Vehicle Control Module (100ms)";
CM_ SG_ 1292 HCM_CLOCK_50C "PRUN Detection of frozen data. Message-PRUN-Diag. The transmitting node adds a message counter of 2bits or more to the end of the last data area (or just before the checksum). The value of the counter, which is initially 0, increments by one everytime new data is transmitted, and returned to zero when reaching the max value. The receiving node lets the first message pass without check, but for second next message and following, it check whether the counter number is different from the previous message.";
CM_ SG_ 1292 ALU_QUESTION_FOR_LBC "B2h = first question 5Dh = second question";
CM_ SG_ 1292 CRC "CRC";
CM_ BO_ 1354 "AC Auto Amp (100ms)";
CM_ SG_ 1354 CCStatusPlusUnknown "12,3c- CC Off; a0,da- CC On";
CM_ SG_ 1354 Unknown_54A_1 "00 (80 in 2013+)";
CM_ SG_ 1354 Unknown_54A_2 "70";
CM_ SG_ 1354 Unknown_54A_3 "06,0a,0b,0f";
CM_ SG_ 1354 ClimateControlSetpoint "This data is only correct while climate control is active. If climate control isswitched OFF or activated by app, byte 4 reads as 0x00.";
CM_ SG_ 1354 Unknown_54A_5 "00";
CM_ SG_ 1354 Unknown_54A_6 "00";
CM_ SG_ 1354 AmbientTempAC "Appears to track ambient (+41)
4f,8c-90";
CM_ BO_ 1118 "??? Unknown sender module(Also empty)";
CM_ BO_ 1438 "Lithium Battery Controller (500ms)";
CM_ BO_ 1153 "??? Unknown sender module (500ms)";
CM_ SG_ 1153 Unknown_481_1 "Dala: Static 0x40, 0x4b while charging";
CM_ SG_ 1153 Unknown_481_2 "Dala: Static 0x00";
CM_ BO_ 912 "On Board Charger (100ms)";
CM_ SG_ 912 OBC_Status_AC_Voltage "ACVOLST - Type of AC voltage";
CM_ SG_ 912 OBC_Flag_QC_Relay_On_Announcemen "FQCRELAYST - QC Relay announcement";
CM_ SG_ 912 OBC_Flag_QC_IR_Sensor "FQCIRSENS - QC IR Sensor";
CM_ SG_ 912 OBC_Maximum_Charge_Power_Out "MAXCHGPOUT - Maximum power supplied by charger in kW";
CM_ SG_ 912 PRUN_390 "Detection of frozen data. Message-PRUN-Diag. The transmitting node adds a message counter of 2bits or more to the end of the last data area (or just before the checksum). The value of the counter, which is initially 0, increments by one everytime new data is transmitted, and returned to zero when reaching the max value. The receiving node lets the first message pass without check, but for second next message and following, it check whether the counter number is different from the previous message.";
CM_ SG_ 912 OBC_Charge_Status "From OVMS code";
CM_ SG_ 912 CSUM_390 "Sum of all nibbles (-4)";
CM_ SG_ 912 OBC_Charge_Power "Actual charger output - From OVMS code";
CM_ BO_ 915 "On Board Charger (100ms)";
CM_ SG_ 915 PRUN_393 "Detection of frozen data. Message-PRUN-Diag. The transmitting node adds a message counter of 2bits or more to the end of the last data area (or just before the checksum). The value of the counter, which is initially 0, increments by one everytime new data is transmitted, and returned to zero when reaching the max value. The receiving node lets the first message pass without check, but for second next message and following, it check whether the counter number is different from the previous message.";
CM_ SG_ 915 Unknown_393_1 "Dala: 20 while idle, 53 while slowcharging";
CM_ SG_ 915 Unknown_393_4 "Dala: Always 20 in logs";
CM_ SG_ 915 CSUM_393 "Deviates from other CSUM: (All nibbles summed together)-1=CSUM";
CM_ BO_ 1539 "Bootup Message, appears once during power on after a few sec";
CM_ BO_ 1657 "Bootup message, sent from OBC when J1772 plug is detected";
CM_ BO_ 1390 "TCU (100ms) RemoteCommand message

Only present on vehicles with TCU (Telematrics Control Unit).This message varies in length depending on which remote command that was requested. Possible commands include, Enable climate control, disable climate control, start charging, auto disable climate control, unlock doors and lock doors. See OVMS implementation for more detail";
CM_ SG_ 1390 Unknown_56E_0 "Dala: 0x46 when car is turned ON, then goes to 0x86 when you turn the vehicle OFF

This message varies in length depending on which remote command that was requested. Possible commands include, Enable climate control, disable climate control, start charging, auto disable climate control, unlock doors and lock doors. See OVMS implementation for more detail";
CM_ BO_ 1549 "??? e-NV200 only, Unknown sender module (100ms) ";
CM_ SG_ 1549 Unknown_60D_0 "Values seen: 00 08 10 14";
CM_ SG_ 1549 Unknown_60D_1 "Values seen: 00 04 06";
VAL_ 1468 LB_Remain_Cap_Segment_Swit_Flag 0 "Remaining capacity" 1 "Full capacity" ;
VAL_ 1468 LB_Output_Power_Limit_Reason 0 "Normal" 1 "Capacity drop" 2 "LBC Malfunction" 3 "High temperature" 4 "Low temperature" 5 "reserved" 6 "reserved" 7 "reserved" ;
VAL_ 1468 LB_Remain_Charge_Time_Condition 0 "Quickcharge" 5 "Normal Charge 6kW Full" 8 "Normal Charge 200V Full" 11 "Normal Charge 100V Full" 18 "Normal Charge 6kW 80%" 21 "Normal Charge 200V 80%" 24 "Normal Charge 100V 80%" ;
VAL_ 475 LB_Relay_Cut_Request 0 "No-Request" 1 "Main Relay OFF Request" 2 "Main Relay OFF Request" 3 "Main Relay OFF Request" ;
VAL_ 475 LB_Failsafe_Status 0 "Normal Start Request" 1 "Normal Stop Request" 2 "Charging Mode Stop Request" 3 "Charging Mode Stop Request & Normal Stop Request" 4 "Caution Lamp Request" 5 "Caution Lamp Request & Normal Stop Request" 6 "Caution Lamp Request & Charging Mode Stop Request" 7 "Caution Lamp Request & Charging Mode Stop Request & Normal Stop Request" ;
VAL_ 475 LB_MainRelayOn_flag 0 "No-Permission" 1 "Main Relay On Permission" ;
VAL_ 475 LB_INTER_LOCK 0 "Not Inter Lock connected" 1 "Inter Lock connected" ;
VAL_ 475 LB_Discharge_Power_Status 0 "Reserved" 1 "Normal limit POUT" 2 "High rate limit POUT" 3 " Immediate limit POUT" ;
VAL_ 1371 LB_IR_Sensor_Malfunction 0 "Normal" 1 "Malfunction" ;
VAL_ 1371 LB_Capacity_Empty 0 "Not Empty" 1 "Battery Empty" ;
VAL_ 1371 LB_SleepEnabled 0 "Reserved" 1 "RefuseToSleep" 2 "ReadyToSleep" 3 "Reserved" ;
VAL_ 476 LB_Charge_Power_Status 0 "Reserved" 1 "Normal limit PIN" 2 "High rate limit PIN" 3 "Immediate limit PIN" ;
VAL_ 476 LB_BPCMAX_UPRATE 0 "BPC MAX Uprate Level 1" 1 "BPC MAX Uprate Level 2" 2 "BPC MAX Uprate Level 3" 3 "BPC MAX Uprate Level 4" 4 "BPC MAX Uprate Level 5" 5 "BPC MAX Uprate Level 6" 6 "BPC MAX Uprate Level 7" 7 "BPC MAX Uprate Level 8" ;
VAL_ 1356 CC_BackScreenDefrost 0 "Off" 1 "On" ;
VAL_ 1356 CC_ClimateControlStatus 0 "Off" 1 "On" ;
VAL_ 1356 CC_ACStatus 0 "Off" 1 "On" ;
VAL_ 282 JoystickGearPosition 2 "Reverse" 3 "Neutral" 4 "Drive/B" 0 "Parked" ;
VAL_ 282 CarOnOffStatus 4 "CarOff" 8 "CarOn" ;
VAL_ 282 ELECTRIC_SHIFT_SYSTEM 1 "SBW_Trq_Down_Req" 3 "ELECTRIC_SHIFT_SYSTEM" 0 "NO_ERROR" ;
VAL_ 468 StatusOfHighVoltagePowerSupply 0 "High Voltage not supplied" 1 "High Voltage supplied" ;
VAL_ 468 Relay_Plus_Output_Status 0 "Main Relay Plus not output" 1 "Main Relay Plus ON" ;
VAL_ 468 ChargeStatus 140 "Charging interrupted" 224 "Charging" ;
VAL_ 468 Inhibitor_Pos 0 "NA" 1 "R" 2 "D" 3 "P" ;
VAL_ 498 TargetCharge_SOC 0 "100%" 1 "Deteroiration Restraint 80%" ;
VAL_ 498 Charge_StatusTransitionReqest 0 "other" 1 "Normal Charge" 2 "Quick Charge" 3 "Stop Request" ;
VAL_ 498 Keep_SOC_Request 0 "Normal charge mode (Initial Value)" 1 "Keep SOC charge mode" ;
VAL_ 498 PCS_Connector_Detection 0 "other" 1 "Vehicle-to-Home mode" ;
VAL_ 1355 ClimateControlStatus1 16 "CC On" 17 "CC Off" 0 "CC On" 1 "CC Off" ;
VAL_ 1355 ClimateVentModeTarget 128 "CC OFF" 136 "Face only" 144 "Face/Feet" 152 "Feet only" 160 "Feet/Defrost" 168 "Defrost only" ;
VAL_ 1355 ClimateVentModeIntake 9 "Recirculate" 18 "Fresh air" 146 "Defrost" ;
VAL_ 1449 ECOmodeActive 2 "ECO On" 1 "ECO Off" 255 "Charging" ;
VAL_ 1472 LB_Historical_Data_Swich_Flag 0 "Not Calculated" 1 "Maximum Data" 2 "Average Data" 3 "Minimum Data" ;
VAL_ 1472 Batt_Heater_Mail_Send_Request 0 "No request" 1 "Mail send request" ;
VAL_ 1472 LB_HEATEXIST 0 "Without Battery Heating" 1 "With Battery Heating" ;
VAL_ 1291 DiagMuxOn_VCM 0 "Storage of CAN mute/absent failures not authorized" 1 "Storage of CAN mute/absent failures" ;
VAL_ 1291 HCM_WakeUpSleepCmd 0 "GoToSleep" 1 "reserved" 2 "reserved" 3 "WakeUp" ;
VAL_ 1291 Batt_Heater_Mail_Send_OK 0 "Mail send NG" 1 "Mail send OK" ;
VAL_ 1291 VcmActivation 0 "NON" 2 "READY" ;
VAL_ 912 OBC_Status_AC_Voltage 0 "No Signal" 1 "100V" 2 "200V" 3 "Abnormal Wave" ;
VAL_ 912 OBC_Flag_QC_Relay_On_Announcemen 1 "Announce OFF" 2 "Announce ON" ;
VAL_ 912 OBC_Flag_QC_IR_Sensor 0 "Without" 1 "With" ;
VAL_ 912 OBC_Charge_Status 1 "Idle OR QC" 2 "Finished" 4 "Charging OR interrupted" 8 "Idle" 9 "Idle" 12 "Plugged in waiting on timer" ;
